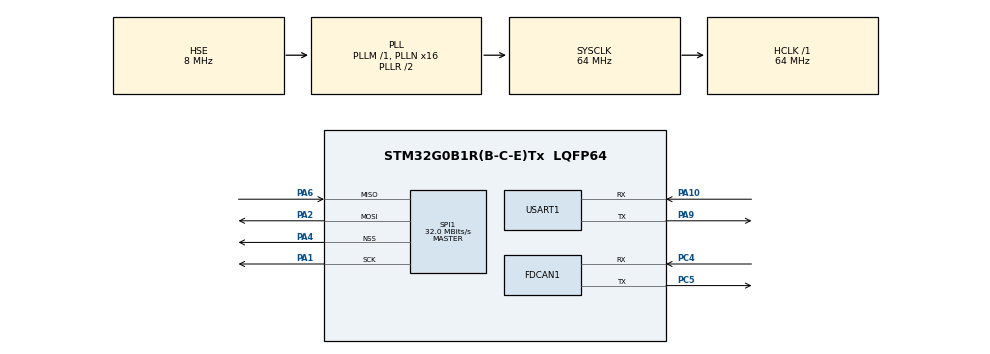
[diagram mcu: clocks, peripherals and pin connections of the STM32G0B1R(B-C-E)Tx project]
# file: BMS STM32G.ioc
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FDCAN1.CalculateBaudRateNominal=800000
FDCAN1.CalculateTimeBitNominal=1250
FDCAN1.CalculateTimeQuantumNominal=250.0
Mcu.Family=STM32G0
Mcu.Name=STM32G0B1R(B-C-E)Tx
Mcu.Package=LQFP64
PA1.Mode=Full_Duplex_Master
PA1.Signal=SPI1_SCK
PA10.Mode=Asynchronous
PA10.Signal=USART1_RX
PA13.Mode=Serial_Wire
PA13.Signal=SYS_SWDIO
PA14-BOOT0.Mode=Serial_Wire
PA14-BOOT0.Signal=SYS_SWCLK
PA2.Mode=Full_Duplex_Master
PA2.Signal=SPI1_MOSI
PA4.Mode=NSS_Signal_Hard_Output
PA4.Signal=SPI1_NSS
PA6.Mode=Full_Duplex_Master
PA6.Signal=SPI1_MISO
PA9.Mode=Asynchronous
PA9.Signal=USART1_TX
PC13.Mode=SYS_WakeUp1
PC13.Signal=SYS_WKUP2
PC4.Mode=FDCAN_Activate
PC4.Signal=FDCAN1_RX
PC5.Mode=FDCAN_Activate
PC5.Signal=FDCAN1_TX
PF0-OSC_IN\ (PF0).Mode=HSE-External-Oscillator
PF0-OSC_IN\ (PF0).Signal=RCC_OSC_IN
PF1-OSC_OUT\ (PF1).Mode=HSE-External-Oscillator
PF1-OSC_OUT\ (PF1).Signal=RCC_OSC_OUT
ProjectManager.HeapSize=0x200
ProjectManager.StackSize=0x400
ProjectManager.TargetToolchain=STM32CubeIDE
RCC.ADCFreq_Value=64000000
RCC.AHBFreq_Value=64000000
RCC.CortexFreq_Value=64000000
RCC.EXTERNAL_CLOCK_VALUE=48000
RCC.HCLKFreq_Value=64000000
RCC.HSE_VALUE=8000000
RCC.HSI48_VALUE=48000000
RCC.HSI_VALUE=16000000
RCC.LSE_VALUE=32768
RCC.PLLN=16
RCC.PLLSourceVirtual=RCC_PLLSOURCE_HSE
RCC.SYSCLKFreq_VALUE=64000000
RCC.SYSCLKSource=RCC_SYSCLKSOURCE_PLLCLK
RCC.USBFreq_Value=48000000
RCC.VCOOutputFreq_Value=128000000
SPI1.CalculateBaudRate=32.0 MBits/s
SPI1.DataSize=SPI_DATASIZE_16BIT
SPI1.Direction=SPI_DIRECTION_2LINES
SPI1.Mode=SPI_MODE_MASTER
SPI1.VirtualNSS=VM_NSSHARD
SPI1.VirtualType=VM_MASTER
USART1.VirtualMode-Asynchronous=VM_ASYNC
VP_SYS_VS_DBSignals.Mode=DisableDeadBatterySignals
board=custom

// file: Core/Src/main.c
/* USER CODE BEGIN Header */
/**
  ******************************************************************************
  * @file           : main.c
  * @brief          : Main program body
  ******************************************************************************
  * @attention
  *
  * Copyright (c) 2025 STMicroelectronics.
  * All rights reserved.
  *
  * This software is licensed under terms that can be found in the LICENSE file
  * in the root directory of this software component.
  * If no LICENSE file comes with this software, it is provided AS-IS.
  *
  ******************************************************************************
  */
/* USER CODE END Header */
#include "main.h"

/* USER CODE BEGIN PD */
#define LTC6804_CS_PIN GPIO_PIN_0
#define LTC6804_CS_PORT GPIOA
/* USER CODE END PD */

FDCAN_HandleTypeDef hfdcan1;

SPI_HandleTypeDef hspi1;

UART_HandleTypeDef huart1;

// DMA completion flags
volatile uint8_t spi_tx_complete = 0;
volatile uint8_t spi_rx_complete = 0;

//Global Acquirable data
uint16_t voltages[12]; //Buffer to store Voltage data

uint16_t temperatures[6]; //Buffer to store Temperature data

void SystemClock_Config(void);
static void MX_GPIO_Init(void);
static void MX_FDCAN1_Init(void);
static void MX_SPI1_Init(void);
static void MX_USART1_UART_Init(void);
// Function to pull CS low, signaling the start of SPI communication
void LTC6804_Select(void) {
    HAL_GPIO_WritePin(LTC6804_CS_PORT, LTC6804_CS_PIN, GPIO_PIN_RESET);//SELECTS SLAVE BY PULLING DOWN LINE
}
// Function to release CS, signaling the end of SPI communication
void LTC6804_Deselect(void) {
    HAL_GPIO_WritePin(LTC6804_CS_PORT, LTC6804_CS_PIN, GPIO_PIN_SET);              // DESELECTS SLAVE BY PULLING UP LINE
}
// DMA transmit complete callback
void HAL_SPI_TxCpltCallback(SPI_HandleTypeDef *hspi) {
    if (hspi->Instance == SPI1) {
        spi_tx_complete = 1;
    }
}
// DMA receive complete callback
void HAL_SPI_RxCpltCallback(SPI_HandleTypeDef *hspi) {
    if (hspi->Instance == SPI1) {
        spi_rx_complete = 1;
    }
}
// Function to send a command to the LTC6804 over SPI using DMA
// cmd: Pointer to the command array
// length: Number of bytes to transmit
void LTC6804_SendCommand_DMA(uint16_t *cmd, uint8_t length) {
    spi_tx_complete = 0;
    LTC6804_Select(); // Select slave by pulling CS low
    HAL_SPI_Transmit_DMA(&hspi1, cmd, length);
    while (!spi_tx_complete); // Wait for DMA transmission to complete
    LTC6804_Deselect(); // Deselect slave by pulling CS high
}
// Function to send a command and read data from the LTC6804 using DMA
// cmd: Pointer to the command array
// data: Pointer to the buffer for received data
// length: Number of bytes to read
void LTC6804_ReadData_DMA(uint16_t *cmd, uint8_t *data, uint8_t length) {
    spi_tx_complete = 0;
    spi_rx_complete = 0;

    LTC6804_Select(); // Pull CS low

    // Send the command using DMA
    HAL_SPI_Transmit_DMA(&hspi1, cmd, 2);
    while (!spi_tx_complete); // Wait for command transmission to complete

    // Receive the data using DMA
    HAL_SPI_Receive_DMA(&hspi1, data, length);
    while (!spi_rx_complete); // Wait for data reception to complete

    LTC6804_Deselect(); // Release CS
}
// Function to start cell voltage conversion
void LTC6804_StartCellVoltageConversion(void) {
    uint16_t cmd = CMD_ADCV; // ADCV Normal Mode, Discharge Disabled
    LTC6804_SendCommand_DMA(cmd, 2);
}
// Function to read cell voltages from the LTC6804
void LTC6804_ReadCellVoltages(uint16_t *voltages) {

    uint16_t cmd[4] = {CMD_RDCVA,CMD_RDCVB,CMD_RDCVC,CMD_RDCVD}; // Array Which Has Commands to Read Every Cell Group Voltages Separately

    for(int i = 0;i<4;i++){
    	uint8_t Temp_Voltage_Buffer[6]; //Temporary Buffer Which Obtains Read Value and reset every iteration
    	LTC6804_ReadData_DMA(cmd[i], Temp_Voltage_Buffer, 6); //Function to read SPI Data through DMA
    	int count = 0; //This varies 0 to 3 in the below loop every time
    	//To make 2x8bit data into a 16bit
    	for(int j = 3*i;j<(3*i)+3;j++){
    		voltages[j] = (Temp_Voltage_Buffer[2*count] | (Temp_Voltage_Buffer[(2*count)+1]));
    		count++;
    	}
    }
}
void LTC6804_StartAuxConversion(void) {
    uint16_t cmd = CMD_ADAX; // ADAX Normal Mode
    LTC6804_SendCommand_DMA(cmd, 2);
}
// Function to read auxiliary data (e.g., temperature values) from the LTC6804

void LTC6804_ReadTemperatures(uint16_t *temperatures) {
	// OBTAIN TEMPERATURE OF GROUP A

    uint16_t cmd = CMD_RDAUXA; // RDAUXA Command to read auxiliary group A
    uint8_t Temp_Group_A[6]; // Buffer for 6 bytes of received data (3 auxiliary values)

    // Send the read command and receive data using DMA
    LTC6804_ReadData_DMA(cmd, Temp_Group_A, 6);

    // Convert the received bytes into auxiliary values
    for (int i = 0; i < 3; i++) {
        temperatures[i] = (Temp_Group_A[2 * i] | (Temp_Group_A[2 * i + 1] << 8)); // Combine LSB and MSB
    }

    // OBTAIN TEMPERATURE OF GROUP B
    uint16_t cmd = CMD_RDAUXB; // RDAUXA Command to read auxiliary group A
    uint8_t Temp_Group_B[6]; // Buffer for 6 bytes of received data (3 auxiliary values)

    // Send the read command and receive data using DMA
    LTC6804_ReadData_DMA(cmd, Temp_Group_B, 6);

    // Convert the received bytes into auxiliary values
    for (int i = 0; i < 3; i++) {
        temperatures[i] = (Temp_Group_B[2 * i] | (Temp_Group_B[2 * i + 1] << 8)); // Combine LSB and MSB
    }
}

int main(void)
{

  /* MCU Configuration--------------------------------------------------------*/

  /* Reset of all peripherals, Initializes the Flash interface and the Systick. */
  HAL_Init();

  /* Configure the system clock */
  SystemClock_Config();

  /* Initialize all configured peripherals */
  MX_GPIO_Init();
  MX_FDCAN1_Init();
  MX_SPI1_Init();
  MX_USART1_UART_Init();

  /* Infinite loop */
  while (1)
  {

  }
}

void SystemClock_Config(void)
{
  RCC_OscInitTypeDef RCC_OscInitStruct = {0};
  RCC_ClkInitTypeDef RCC_ClkInitStruct = {0};

  /** Configure the main internal regulator output voltage
  */
  HAL_PWREx_ControlVoltageScaling(PWR_REGULATOR_VOLTAGE_SCALE1);

  /** Initializes the RCC Oscillators according to the specified parameters
  * in the RCC_OscInitTypeDef structure.
  */
  RCC_OscInitStruct.OscillatorType = RCC_OSCILLATORTYPE_HSE;
  RCC_OscInitStruct.HSEState = RCC_HSE_ON;
  RCC_OscInitStruct.PLL.PLLState = RCC_-PLL_ON;
  RCC_OscInitStruct.PLL.PLLSource = RCC_PLLSOURCE_HSE;
  RCC_OscInitStruct.PLL.PLLM = RCC_PLLM_DIV1;
  RCC_OscInitStruct.PLL.PLLN = 16;
  RCC_OscInitStruct.PLL.PLLP = RCC_PLLP_DIV2;
  RCC_OscInitStruct.PLL.PLLQ = RCC_PLLQ_DIV2;
  RCC_OscInitStruct.PLL.PLLR = RCC_PLLR_DIV2;
  if (HAL_RCC_OscConfig(&RCC_OscInitStruct) != HAL_OK)
  {
    Error_Handler();
  }

  /** Initializes the CPU, AHB and APB buses clocks
  */
  RCC_ClkInitStruct.ClockType = RCC_CLOCKTYPE_HCLK|RCC_CLOCKTYPE_SYSCLK
                              |RCC_CLOCKTYPE_PCLK1;
  RCC_ClkInitStruct.SYSCLKSource = RCC_SYSCLKSOURCE_PLLCLK;
  RCC_ClkInitStruct.AHBCLKDivider = RCC_SYSCLK_DIV1;
  RCC_ClkInitStruct.APB1CLKDivider = RCC_HCLK_DIV1;

  if (HAL_RCC_ClockConfig(&RCC_ClkInitStruct, FLASH_LATENCY_2) != HAL_OK)
  {
    Error_Handler();
  }
}

static void MX_FDCAN1_Init(void)
{

  hfdcan1.Instance = FDCAN1;
  hfdcan1.Init.ClockDivider = FDCAN_CLOCK_DIV1;
  hfdcan1.Init.FrameFormat = FDCAN_FRAME_CLASSIC;
  hfdcan1.Init.Mode = FDCAN_MODE_NORMAL;
  hfdcan1.Init.AutoRetransmission = DISABLE;
  hfdcan1.Init.TransmitPause = DISABLE;
  hfdcan1.Init.ProtocolException = DISABLE;
  hfdcan1.Init.NominalPrescaler = 16;
  hfdcan1.Init.NominalSyncJumpWidth = 1;
  hfdcan1.Init.NominalTimeSeg1 = 2;
  hfdcan1.Init.NominalTimeSeg2 = 2;
  hfdcan1.Init.DataPrescaler = 1;
  hfdcan1.Init.DataSyncJumpWidth = 1;
  hfdcan1.Init.DataTimeSeg1 = 1;
  hfdcan1.Init.DataTimeSeg2 = 1;
  hfdcan1.Init.StdFiltersNbr = 0;
  hfdcan1.Init.ExtFiltersNbr = 0;
  hfdcan1.Init.TxFifoQueueMode = FDCAN_TX_FIFO_OPERATION;
  if (HAL_FDCAN_Init(&hfdcan1) != HAL_OK)
  {
    Error_Handler();
  }

}

static void MX_SPI1_Init(void)
{

  /* SPI1 parameter configuration*/
  hspi1.Instance = SPI1;
  hspi1.Init.Mode = SPI_MODE_MASTER;
  hspi1.Init.Direction = SPI_DIRECTION_2LINES;
  hspi1.Init.DataSize = SPI_DATASIZE_16BIT;
  hspi1.Init.CLKPolarity = SPI_POLARITY_LOW;
  hspi1.Init.CLKPhase = SPI_PHASE_1EDGE;
  hspi1.Init.NSS = SPI_NSS_HARD_OUTPUT;
  hspi1.Init.BaudRatePrescaler = SPI_BAUDRATEPRESCALER_2;
  hspi1.Init.FirstBit = SPI_FIRSTBIT_MSB;
  hspi1.Init.TIMode = SPI_TIMODE_DISABLE;
  hspi1.Init.CRCCalculation = SPI_CRCCALCULATION_DISABLE;
  hspi1.Init.CRCPolynomial = 7;
  hspi1.Init.CRCLength = SPI_CRC_LENGTH_DATASIZE;
  hspi1.Init.NSSPMode = SPI_NSS_PULSE_ENABLE;
  if (HAL_SPI_Init(&hspi1) != HAL_OK)
  {
    Error_Handler();
  }

}

static void MX_USART1_UART_Init(void)
{

  huart1.Instance = USART1;
  huart1.Init.BaudRate = 115200;
  huart1.Init.WordLength = UART_WORDLENGTH_8B;
  huart1.Init.StopBits = UART_STOPBITS_1;
  huart1.Init.Parity = UART_PARITY_NONE;
  huart1.Init.Mode = UART_MODE_TX_RX;
  huart1.Init.HwFlowCtl = UART_HWCONTROL_NONE;
  huart1.Init.OverSampling = UART_OVERSAMPLING_16;
  huart1.Init.OneBitSampling = UART_ONE_BIT_SAMPLE_DISABLE;
  huart1.Init.ClockPrescaler = UART_PRESCALER_DIV1;
  huart1.AdvancedInit.AdvFeatureInit = UART_ADVFEATURE_NO_INIT;
  if (HAL_UART_Init(&huart1) != HAL_OK)
  {
    Error_Handler();
  }
  if (HAL_UARTEx_SetTxFifoThreshold(&huart1, UART_TXFIFO_THRESHOLD_1_8) != HAL_OK)
  {
    Error_Handler();
  }
  if (HAL_UARTEx_SetRxFifoThreshold(&huart1, UART_RXFIFO_THRESHOLD_1_8) != HAL_OK)
  {
    Error_Handler();
  }
  if (HAL_UARTEx_DisableFifoMode(&huart1) != HAL_OK)
  {
    Error_Handler();
  }

}

static void MX_GPIO_Init(void)
{

  /* GPIO Ports Clock Enable */
  __HAL_RCC_GPIOC_CLK_ENABLE();
  __HAL_RCC_GPIOF_CLK_ENABLE();
  __HAL_RCC_GPIOA_CLK_ENABLE();

}

void Error_Handler(void)
{
  __disable_irq();
  while (1)
  {
  }
}
